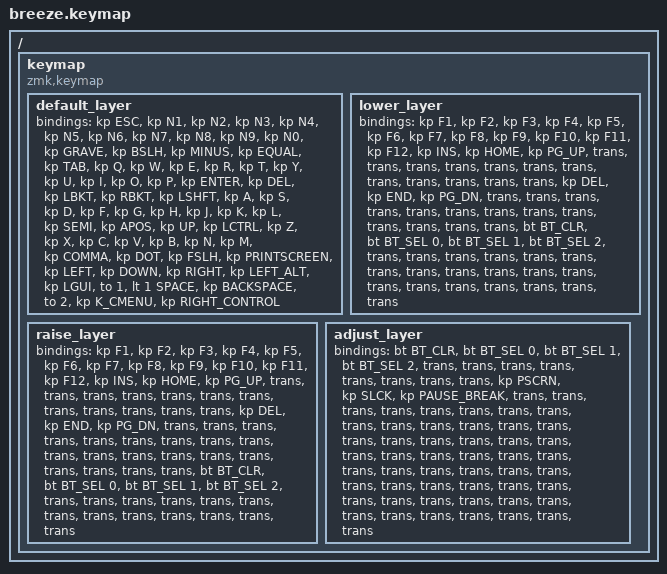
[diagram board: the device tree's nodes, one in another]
/*
 * Copyright (c) 2022 The ZMK Contributors
 *
 * SPDX-License-Identifier: MIT
 */

#include <behaviors.dtsi>
#include <dt-bindings/zmk/bt.h>
#include <dt-bindings/zmk/keys.h>

/ {
    keymap {
        compatible = "zmk,keymap";

        default_layer {
            // Ref: https://zmkfirmware.dev/docs/codes/
            // ----------------------------------------------------------------------------------------------------------------------------------
            // |   `   |  1  |  2  |  3    |  4   |  5   |                               |  6   |  7    |  8    |  9   |   0   | -/_  | |  \  | HOME | PG UP|
            // |  TAB  |  Q  |  W  |  E    |  R   |  T   |                               |  Y   |  U    |  I    |  O   |   P   |  [   | |  ]  | END  | PG DN|
            // |  CTRL |  A  |  S  |  D    |  F   |  G   |                               |  H   |  J    |  K    |  L   |   ;   |  '   | |     |  UP  |      |
            // |  SHFT |  Z  |  X  |  C    |  V   |  B   |                               |  N   |  M    |  ,    |  .   |   /   |  RET | |  L  |  DN  |  R   |
            //                     | LOWER | ALT  | GUI  | LOWER/SPACE |   | RAISE/SPACE | BKSP | DEL   | RAISE |

            bindings = <
&kp ESC  &kp N1  &kp N2  &kp N3  &kp N4  &kp N5  &kp N6  &kp N7  &kp N8  &kp N9  &kp N0  &kp GRAVE  &kp BSLH  &kp MINUS  &kp EQUAL  &kp TAB  &kp Q  &kp W  &kp E  &kp R  &kp T  &kp Y  &kp U  &kp I  &kp O  &kp P  &kp ENTER  &kp DEL  &kp LBKT  &kp RBKT  &kp LSHFT  &kp A  &kp S  &kp D  &kp F  &kp G  &kp H  &kp J  &kp K  &kp L  &kp SEMI  &kp APOS  &kp UP  &kp LCTRL  &kp Z  &kp X  &kp C  &kp V  &kp B  &kp N  &kp M  &kp COMMA  &kp DOT  &kp FSLH  &kp PRINTSCREEN  &kp LEFT  &kp DOWN  &kp RIGHT  &kp LEFT_ALT  &kp LGUI  &to 1  &lt 1 SPACE  &kp BACKSPACE  &to 2  &kp K_CMENU  &kp RIGHT_CONTROL
            >;
        };

        lower_layer {
            // ---------------------------------------------------------------------------------------------------------------------------------- 
            // |   F1  |  F2  |  F3 |  F4  |  F5   |  F6  |                   |  F7  |  F8  |  F9  |  F10 |  F11  |  F12  | |   =   | PSCRN|      | 
            // |CMD-TAB|      |     |      |       |  [   |                   |  ]   |      |      |      |       |       | |       | Mute | Play | 
            // |       | CMD-A|     |      |       |      |                   |  L   |  DN  |  UP  |  R   |       |       | |       | Vol+ |      | 
            // |  CAPS | CMD-Z| CUT | COPY | PASTE |  {   |                   |  }   |      |      |      |       |       | | Prev  | Vol- | Next | 
            //                      |      |       |      |        |  |  RET  |      |  INS |ADJUST|

            bindings = <
&kp F1  &kp F2  &kp F3  &kp F4  &kp F5  &kp F6  &kp F7  &kp F8  &kp F9  &kp F10  &kp F11  &kp F12  &kp INS  &kp HOME  &kp PG_UP  &trans  &trans  &trans  &trans  &trans  &trans  &trans  &trans  &trans  &trans  &trans  &trans  &kp DEL  &kp END  &kp PG_DN  &trans  &trans  &trans  &trans  &trans  &trans  &trans  &trans  &trans  &trans  &trans  &trans  &trans  &bt BT_CLR  &bt BT_SEL 0  &bt BT_SEL 1  &bt BT_SEL 2  &trans  &trans  &trans  &trans  &trans  &trans  &trans  &trans  &trans  &trans  &trans  &trans  &trans  &trans  &trans  &trans  &trans  &trans  &trans
            >;
        };

        raise_layer {
            // ---------------------------------------------------------------------------------------------------------------------------------- 
            // | ESC |      |      |      |      |        |                   |      |      |      |      |       |       | |     |      |      | 
            // |     |      |      |      |      |        |                   |      |      |      |      |       |       | |     |      |      | 
            // |     |CTRL-A|      |      |      |        |                   | HOME | PGDN | PGUP | END  |       |       | |     |      |      | 
            // |     |CTRL-Z|CTRL-X|CTRL-C|CTRL-V|        |                   |      |      |      |      |       |       | |     |      |      | 
            //                     |      |      |        |  BKSP  |  |       |      |      |      |

            bindings = <
&kp F1  &kp F2  &kp F3  &kp F4  &kp F5  &kp F6  &kp F7  &kp F8  &kp F9  &kp F10  &kp F11  &kp F12  &kp INS  &kp HOME  &kp PG_UP  &trans  &trans  &trans  &trans  &trans  &trans  &trans  &trans  &trans  &trans  &trans  &trans  &kp DEL  &kp END  &kp PG_DN  &trans  &trans  &trans  &trans  &trans  &trans  &trans  &trans  &trans  &trans  &trans  &trans  &trans  &trans  &trans  &trans  &trans  &trans  &trans  &bt BT_CLR  &bt BT_SEL 0  &bt BT_SEL 1  &bt BT_SEL 2  &trans  &trans  &trans  &trans  &trans  &trans  &trans  &trans  &trans  &trans  &trans  &trans  &trans
            >;
        };

        adjust_layer {
            // ---------------------------------------------------------------------------------------------------------------------------------- 
            // | BT1 | BT2 | BT3 | BT4  |      | BT_CLR |                   |      |       |       |      |       |       | |     |      |      | 
            // |     |     |     |      |      |        |                   |      |       |       |      |       |       | |     |      |      | 
            // |     |     |     |      |      |        |                   |      |       |       |      |       |       | |     |      |      | 
            // |     |     |     |      |      |        |                   |      |       |       |      |       |       | |     |      |      | 
            //                   |      |      |        |        |  |       |      |       |       |

            bindings = <
&bt BT_CLR  &bt BT_SEL 0  &bt BT_SEL 1  &bt BT_SEL 2  &trans  &trans  &trans  &trans  &trans  &trans  &trans  &trans  &kp PSCRN  &kp SLCK  &kp PAUSE_BREAK  &trans  &trans  &trans  &trans  &trans  &trans  &trans  &trans  &trans  &trans  &trans  &trans  &trans  &trans  &trans  &trans  &trans  &trans  &trans  &trans  &trans  &trans  &trans  &trans  &trans  &trans  &trans  &trans  &trans  &trans  &trans  &trans  &trans  &trans  &trans  &trans  &trans  &trans  &trans  &trans  &trans  &trans  &trans  &trans  &trans  &trans  &trans  &trans  &trans  &trans  &trans
            >;
        };
    };
};
